# Cortex_M7 register map
Vendor: ARM Ltd.; File version: 1.2
CPU: CM7 r0p0, little endian, MPU, no FPU, vendor SysTick, 8 interrupt priority bits
Registers are 32-bit, read-write, no defined reset value unless marked. A register's access mark holds for its fields unless they carry their own. Offsets are from the block's base; [hi:lo] are bit positions; {n}, {i} and the like mark numbered series; 'fields as' and 'values as' point back to an identical list.

## Control — System Control registers
Base 0xE000E008
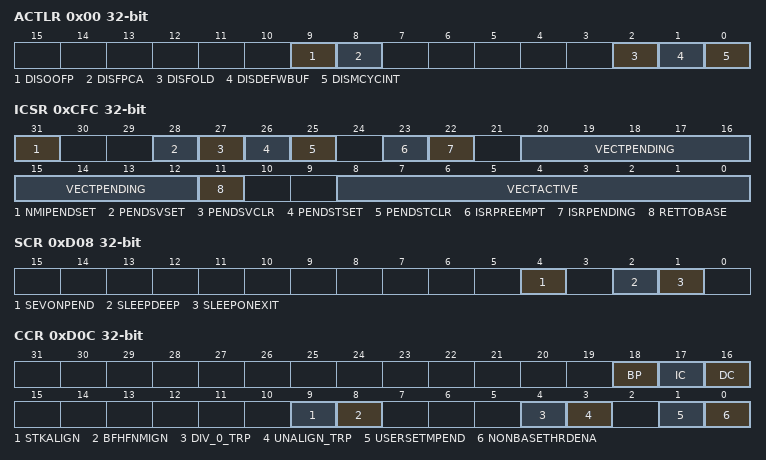
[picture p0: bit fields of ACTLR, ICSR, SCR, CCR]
0x00 ACTLR
  [all] fields
    0=Enabled; 1=Disabled
  [9] DISOOFP
  [8] DISFPCA
  [2] DISFOLD
  [1] DISDEFWBUF
  [0] DISMCYCINT
0xCFC ICSR
  [31] NMIPENDSET
    0=Do_not_activate; 1=Activate_NMI_exception
  [28] PENDSVSET
    0=Do_not_set; 1=Set_pending
  [27] PENDSVCLR
    0=Do_not_clear; 1=Clear_pending
  [26] PENDSTSET
    0=Do_not_set; 1=Set_pending
  [25] PENDSTCLR
    0=Do_not_clear; 1=Clear_pending
  [23] ISRPREEMPT
    0=Will_not_service; 1=Will_service_pending_exception
  [22] ISRPENDING
    0=Interrupt_not_pending; 1=Interrupt_pending
  [20:12] VECTPENDING
  [11] RETTOBASE
    0=Active_exception; 1=No_Active_Exception
  [8:0] VECTACTIVE
0xD00 VTOR
  [29] TBLBASE
    0=CODE; 1=SRAM
  [31:7] TBLOFF
0xD04 AIRCR
  [31:16] VECTKEY
  [31:16] VECTKEYSTAT
  [15] ENDIANNESS
    0=Little_endian; 1=Big_endian
  [10:8] PRIGROUP
  [2] SYSRESETREQ
    0=Do_not_request_reset; 1=Request_reset
  [1] VECTCLRACTIVE
    0=Do_not_clear; 1=Clear_state_information
0xD08 SCR
  [4] SEVONPEND
    0=Not_wakeup; 1=Wakeup
  [2] SLEEPDEEP
    0=Not_deep_sleep; 1=Deep_sleep
  [1] SLEEPONEXIT
    0=Do_not_enter; 1=Enter
0xD0C CCR
  [18] BP
    0=Disabled; 1=Enabled
  [17] IC
    0=Disabled; 1=Enabled
  [16] DC
    0=Disabled; 1=Enabled
  [9] STKALIGN
    0=_4_Byte; 1=_8_Byte
  [8] BFHFNMIGN
    0=Fault; 1=Ignore
  [4] DIV_0_TRP
    0=Disabled; 1=Enabled
  [3] UNALIGN_TRP
    0=Disabled; 1=Enabled
  [1] USERSETMPEND
    0=Disabled; 1=Enabled
  [0] NONBASETHRDENA
    0=Disabled; 1=Enabled
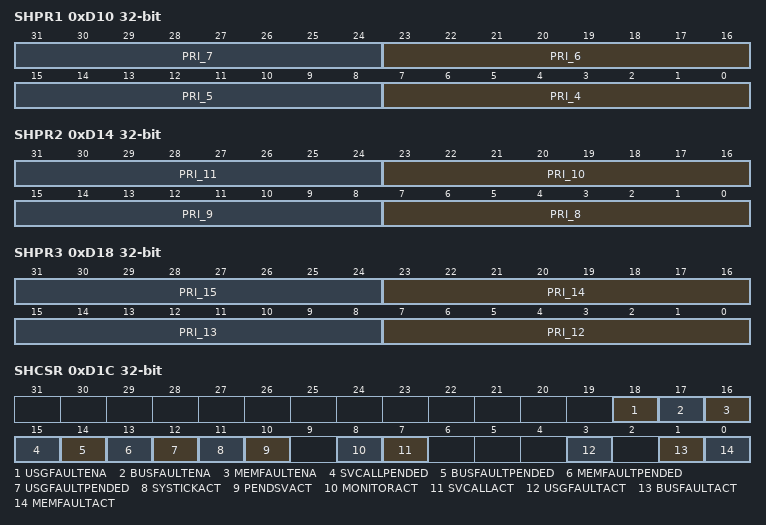
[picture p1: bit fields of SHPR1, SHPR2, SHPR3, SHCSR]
0xD10 SHPR1
  [8n-25:8n-32] PRI_{n} (n=4..7)
0xD14 SHPR2
  [8n-57:8n-64] PRI_{n} (n=8..11)
0xD18 SHPR3
  [8n-89:8n-96] PRI_{n} (n=12..15)
0xD1C SHCSR
  [18] USGFAULTENA
    0=Disabled; 1=Enabled
  [17] BUSFAULTENA
    0=Disabled; 1=Enabled
  [16] MEMFAULTENA
    0=Disabled; 1=Enabled
  [15] SVCALLPENDED
    0=Not_pending; 1=Pending
  [14] BUSFAULTPENDED
    0=Not_pending; 1=Pending
  [13] MEMFAULTPENDED
    0=Not_pending; 1=Pending
  [12] USGFAULTPENDED
    0=Not_pending; 1=Pending
  [11] SYSTICKACT
    0=Not_active; 1=Active
  [10] PENDSVACT
    0=Not_active; 1=Active
  [8] MONITORACT
    0=Not_active; 1=Active
  [7] SVCALLACT
    0=Not_active; 1=Active
  [3] USGFAULTACT
    0=Not_active; 1=Active
  [1] BUSFAULTACT
    0=Not_active; 1=Active
  [0] MEMFAULTACT
    0=Not_active; 1=Active
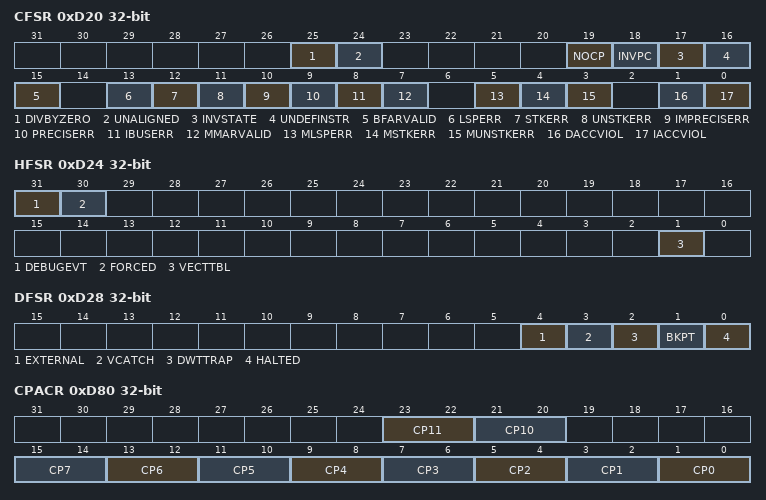
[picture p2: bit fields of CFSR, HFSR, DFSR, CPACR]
0xD20 CFSR
  [25] DIVBYZERO
    0=Not_occurred; 1=Occurred
  [24] UNALIGNED
    0=Not_occurred; 1=Occurred
  [19] NOCP
    0=Not_occurred; 1=Occurred
  [18] INVPC
    0=Not_occurred; 1=Occurred
  [17] INVSTATE
    0=Not_occurred; 1=Occurred
  [16] UNDEFINSTR
    0=Not_occurred; 1=Occurred
  [15] BFARVALID
    0=Not_valid; 1=Valid
  [13] LSPERR
    0=Not_occurred; 1=Occurred
  [12] STKERR
    0=Not_occurred; 1=Occurred
  [11] UNSTKERR
    0=Not_occurred; 1=Occurred
  [10] IMPRECISERR
    0=Not_occurred; 1=Occurred
  [9] PRECISERR
    0=Not_occurred; 1=Occurred
  [8] IBUSERR
    0=Not_occurred; 1=Occurred
  [7] MMARVALID
    0=Not_valid; 1=Valid
  [5] MLSPERR
    0=Not_occurred; 1=Occurred
  [4] MSTKERR
    0=Not_occurred; 1=Occurred
  [3] MUNSTKERR
    0=Not_occurred; 1=Occurred
  [1] DACCVIOL
    0=Not_occurred; 1=Occurred
  [0] IACCVIOL
    0=Not_occurred; 1=Occurred
0xD24 HFSR
  [all] fields
    0=Not_occurred; 1=Occurred
  [31] DEBUGEVT
  [30] FORCED
  [1] VECTTBL
0xD28 DFSR
  [4] EXTERNAL, [3] VCATCH, [2] DWTTRAP, [1] BKPT, [0] HALTED
0xD2C MMFAR
0xD30 BFAR
0xD34 AFSR
0xD80 CPACR
  [all] fields
    0=Access_denied; 1=Privileged_mode_access_only; 3=Full_access
  [23:22] CP11
  [21:20] CP10
  [2n+1:2n] CP{n} (n=0..7)
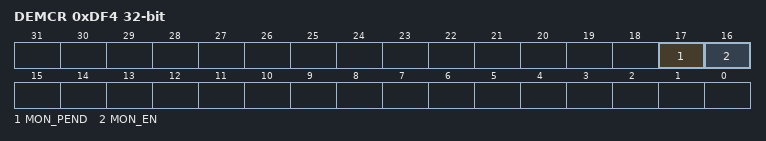
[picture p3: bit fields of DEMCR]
0xDF4 DEMCR ro
  [17] MON_PEND, [16] MON_EN
0xEF8 STIR wo
  [8:0] INTID

## ImpDef — Implementation defined registers
Base 0xE000EF90
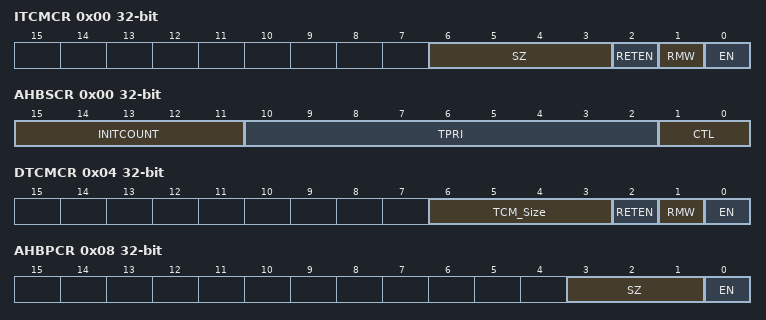
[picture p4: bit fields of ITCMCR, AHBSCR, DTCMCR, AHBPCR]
0x00 ITCMCR
  [6:3] SZ
    0=No_TCM; 3=_4KB; 4=_8KB; 5=_16KB; 6=_32KB; 7=_64KB; 8=_256KB; 9=_256KB; 10=_512KB; 11=_1MB; 12=_2MB; 13=_4MB; 14=_8MB; 15=_16MB
  [2] RETEN
    0=Disabled; 1=Enabled
  [1] RMW
    0=Disabled; 1=Enabled
  [0] EN
    0=Disabled; 1=Enabled
0x00 AHBSCR
  [15:11] INITCOUNT, [10:2] TPRI, [1:0] CTL
0x04 DTCMCR
  [6:3] TCM_Size
    values as ITCMCR.SZ
  [2] RETEN
    0=Disabled; 1=Enabled
  [1] RMW
    0=Disabled; 1=Enabled
  [0] EN
    0=Disabled; 1=Enabled
0x08 AHBPCR
  [3:1] SZ
    1=_64MB; 2=_128MB; 3=_256MB; 4=_512MB
  [0] EN
    0=Disabled; 1=Enabled
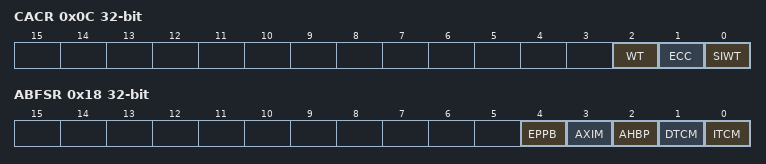
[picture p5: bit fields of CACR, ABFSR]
0x0C CACR
  [2] WT
    0=Disabled; 1=Enabled
  [1] ECC
    0=Enabled; 1=Disabled
  [0] SIWT
    0=Disabled; 1=Enabled
0x18 ABFSR
  [all] fields
    0=Disabled; 1=Enabled
  [4] EPPB
  [3] AXIM
  [2] AHBP
  [1] DTCM
  [0] ITCM

## MPU — Memory Protection Unit
Base 0xE000ED90
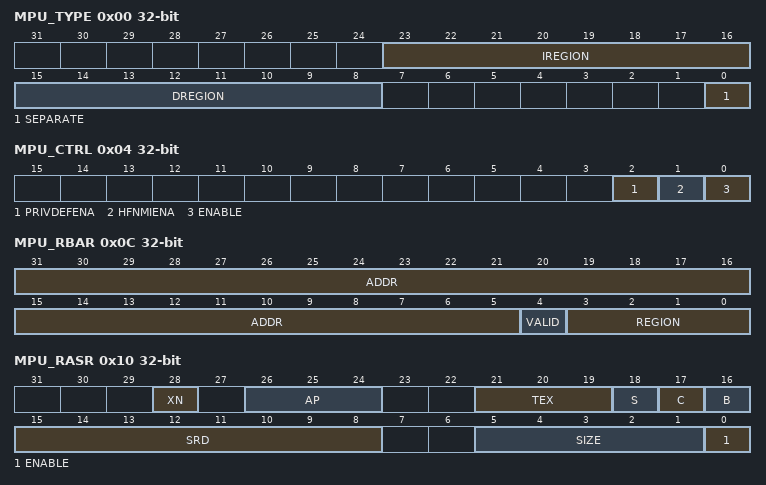
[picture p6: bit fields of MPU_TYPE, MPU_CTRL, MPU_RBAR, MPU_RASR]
0x00 MPU_TYPE ro
  [23:16] IREGION
  [15:8] DREGION
  [0] SEPARATE
    0=Uniform; 1=Separate
0x04 MPU_CTRL — MPU Control Register
  [all] fields
    0=Disabled; 1=Enabled
  [2] PRIVDEFENA
  [1] HFNMIENA
  [0] ENABLE
0x08 MPU_RNR — MPU Region Number register
  [7:0] REGION
0x0C MPU_RBAR — MPU Region Base Address Register
  [31:5] ADDR
  [4] VALID
    0=Not_valid; 1=Valid
  [3:0] REGION
0x10 MPU_RASR — MPU Region Attribute and Size Register
  [28] XN
    0=Execution_Permitted; 1=Execution_Not_Permitted
  [26:24] AP
    0=Any_access_generates_a_permission_fault; 1=Privileged_access_only; 2=Any_unprivileged_write_generates_a_permission_fault; 3=Full_access; 5=Privileged_read_only; 6=Privileged_and_unprivileged_read_only; 7=Privileged_and_unprivileged_read_only
  [21:19] TEX
  [18] S
  [17] C
  [16] B
  [15:8] SRD
  [5:1] SIZE
  [0] ENABLE
    0=Disabled; 1=Enabled
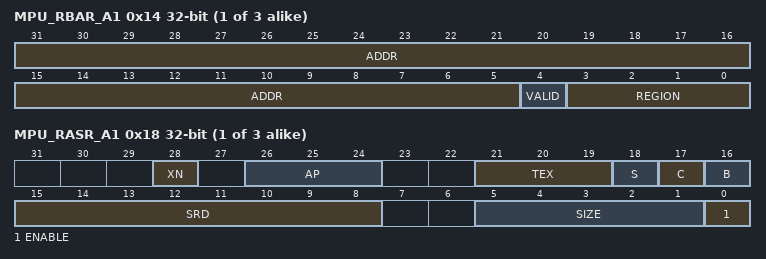
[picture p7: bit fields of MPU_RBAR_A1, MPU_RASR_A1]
{0xC+8i} MPU_RBAR_A{i} (i=1..3) — MPU Alias {i} Region Base Address register
  [31:5] ADDR
  [4] VALID
    0=Not_valid; 1=Valid
  [3:0] REGION
{0x10+8i} MPU_RASR_A{i} (i=1..3) — MPU Alias {i} Region Attribute and Size register
  fields as MPU_RASR

## NVIC — Nested Vectored Interrupt Controller registers
Base 0xE000E004
0x00 ICTR ro — Interrupt Controller Type Register
  [3:0] INTLINESNUM
{0xFC+4i} NVIC_ISER{i} reset 0x0 (i=0..7) — Interrupt Set-Enable Register
  [31:0] SETENA
{0x17C+4i} NVIC_ICER{i} reset 0x0 (i=0..7) — Interrupt Clear-Enable Register
  [31:0] CLRENA
{0x1FC+4i} NVIC_ISPR{i} reset 0x0 (i=0..7) — Interrupt Set-Pending Register
  [31:0] SETPEND
{0x27C+4i} NVIC_ICPR{i} reset 0x0 (i=0..7) — Interrupt Clear-Pending Register
  [31:0] CLRPEND
{0x2FC+4i} NVIC_IABR{i} reset 0x0 (i=0..7) — Interrupt Active Bit Register
  [31:0] ACTIVE
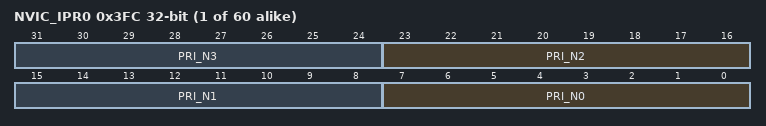
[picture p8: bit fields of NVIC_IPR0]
{0x3FC+4i} NVIC_IPR{i} (i=0..59)
  [8n+7:8n] PRI_N{n} (n=0..3)

## SysTick — System Timer registers
Base 0xE000E010
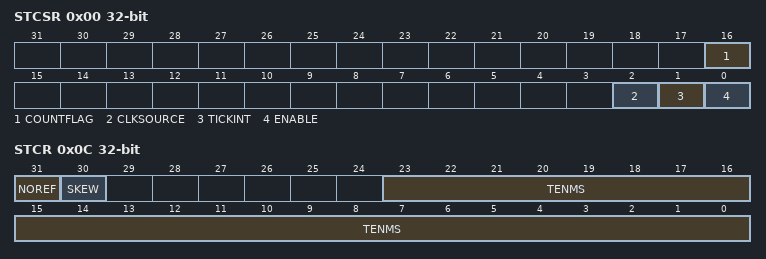
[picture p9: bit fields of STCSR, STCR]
0x00 STCSR
  [16] COUNTFLAG
    0=not_counted_to_0; 1=counted_to_0
  [2] CLKSOURCE
    0=External_clock; 1=Processor_clock
  [1] TICKINT
    0=Does_not_affect_exception_status; 1=Changes_exception_status
  [0] ENABLE
    0=Counter_disabled; 1=Counter_operating
0x04 STRVR
  [23:0] RELOAD
0x08 STCVR
  [23:0] CURRENT
0x0C STCR ro
  [31] NOREF
    0=Implemented; 1=Not_implemented
  [30] SKEW
    0=Exact; 1=Inexact
  [23:0] TENMS

## Notices in the file
Copyright (c) 2021 STMicroelectronics.
SPDX-License-Identifier: Apache-2.0
Licensed under the Apache License, Version 2.0 (the "License");
you may not use this file except in compliance with the License.
You may obtain a copy of the License at
http://www.apache.org/licenses/LICENSE-2.0
Unless required by applicable law or agreed to in writing, software
distributed under the License is distributed on an "AS IS" BASIS,
WITHOUT WARRANTIES OR CONDITIONS OF ANY KIND, either express or implied.
See the License for the specific language governing permissions and
limitations under the License.
